VERSION "Volvo_J1939_Proprietary_v2.0"

NS_ :

BS_:

BU_: ACM_Volvo

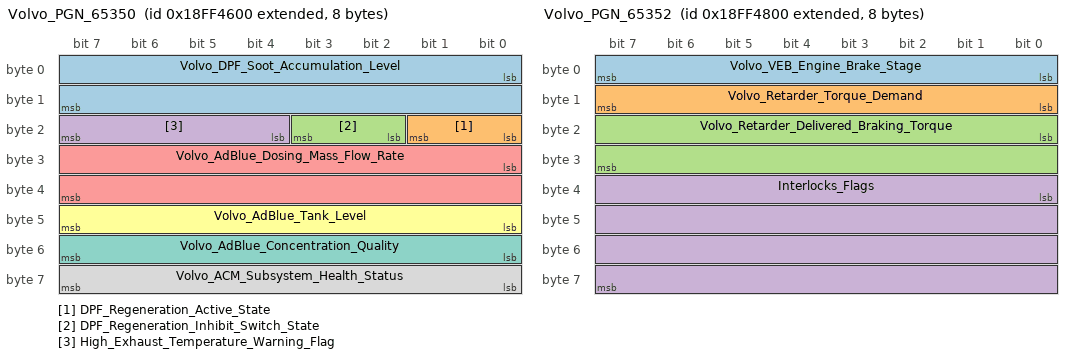
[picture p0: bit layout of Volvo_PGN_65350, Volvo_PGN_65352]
BO_ 2566866432 Volvo_PGN_65350: 8 ACM_Volvo
 SG_ Volvo_DPF_Soot_Accumulation_Level : 0|16@1+ (0.1,0) [0|6553.5] "g" Vector__XXX
 SG_ DPF_Regeneration_Active_State : 16|2@1+ (1,0) [0|3] "" Vector__XXX
 SG_ DPF_Regeneration_Inhibit_Switch_State : 18|2@1+ (1,0) [0|3] "" Vector__XXX
 SG_ High_Exhaust_Temperature_Warning_Flag : 20|4@1+ (1,0) [0|15] "" Vector__XXX
 SG_ Volvo_AdBlue_Dosing_Mass_Flow_Rate : 24|16@1+ (0.05,0) [0|3276.75] "g/s" Vector__XXX
 SG_ Volvo_AdBlue_Tank_Level : 40|8@1+ (0.4,0) [0|102] "%" Vector__XXX
 SG_ Volvo_AdBlue_Concentration_Quality : 48|8@1+ (0.2,0) [0|51] "%" Vector__XXX
 SG_ Volvo_ACM_Subsystem_Health_Status : 56|8@1+ (1,0) [0|255] "" Vector__XXX

BO_ 2566866944 Volvo_PGN_65352: 8 ACM_Volvo
 SG_ Volvo_VEB_Engine_Brake_Stage : 0|8@1+ (1,0) [0|255] "" Vector__XXX
 SG_ Volvo_Retarder_Torque_Demand : 8|8@1+ (0.4,0) [0|102] "%" Vector__XXX
 SG_ Volvo_Retarder_Delivered_Braking_Torque : 16|16@1+ (0.5,-1000) [-1000|31767.5] "Nm" Vector__XXX
 SG_ Interlocks_Flags : 32|32@1+ (1,0) [0|4.29497e+09] "" Vector__XXX

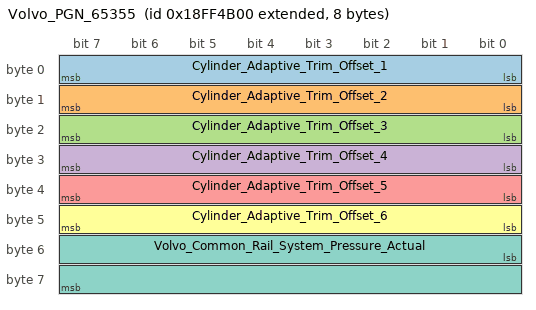
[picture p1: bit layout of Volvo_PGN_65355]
BO_ 2566867712 Volvo_PGN_65355: 8 ACM_Volvo
 SG_ Cylinder_Adaptive_Trim_Offset_1 : 0|8@1+ (0.1,-12.8) [-12.8|12.7] "mg/stroke" Vector__XXX
 SG_ Cylinder_Adaptive_Trim_Offset_2 : 8|8@1+ (0.1,-12.8) [-12.8|12.7] "mg/stroke" Vector__XXX
 SG_ Cylinder_Adaptive_Trim_Offset_3 : 16|8@1+ (0.1,-12.8) [-12.8|12.7] "mg/stroke" Vector__XXX
 SG_ Cylinder_Adaptive_Trim_Offset_4 : 24|8@1+ (0.1,-12.8) [-12.8|12.7] "mg/stroke" Vector__XXX
 SG_ Cylinder_Adaptive_Trim_Offset_5 : 32|8@1+ (0.1,-12.8) [-12.8|12.7] "mg/stroke" Vector__XXX
 SG_ Cylinder_Adaptive_Trim_Offset_6 : 40|8@1+ (0.1,-12.8) [-12.8|12.7] "mg/stroke" Vector__XXX
 SG_ Volvo_Common_Rail_System_Pressure_Actual : 48|16@1+ (0.1,0) [0|6553.5] "MPa" Vector__XXX

BA_DEF_ BO_  "J1939PGN" INT 0 262143;
BA_DEF_DEF_  "J1939PGN" 0;
CM_ SG_ 2566866432 DPF_Regeneration_Active_State "enum values: see Volvo decoder MAP in project source";
CM_ SG_ 2566866432 DPF_Regeneration_Inhibit_Switch_State "enum values: see Volvo decoder MAP in project source";
CM_ SG_ 2566866432 High_Exhaust_Temperature_Warning_Flag "enum values: see Volvo decoder MAP in project source";
CM_ SG_ 2566866432 Volvo_ACM_Subsystem_Health_Status "enum values: see Volvo decoder MAP in project source";
CM_ BO_ 2566866432 "PGN 65350 (0xFF46): Volvo proprietary layout derived from project OEM decoder";
CM_ SG_ 2566866944 Volvo_VEB_Engine_Brake_Stage "enum values: see Volvo decoder MAP in project source";
CM_ SG_ 2566866944 Interlocks_Flags "enum values: see Volvo decoder MAP in project source";
CM_ BO_ 2566866944 "PGN 65352 (0xFF48): Volvo proprietary layout derived from project OEM decoder";
CM_ BO_ 2566867712 "PGN 65355 (0xFF4B): Volvo proprietary layout derived from project OEM decoder";
BA_ "J1939PGN" BO_ 2566866432 65350;
BA_ "J1939PGN" BO_ 2566866944 65352;
BA_ "J1939PGN" BO_ 2566867712 65355;
